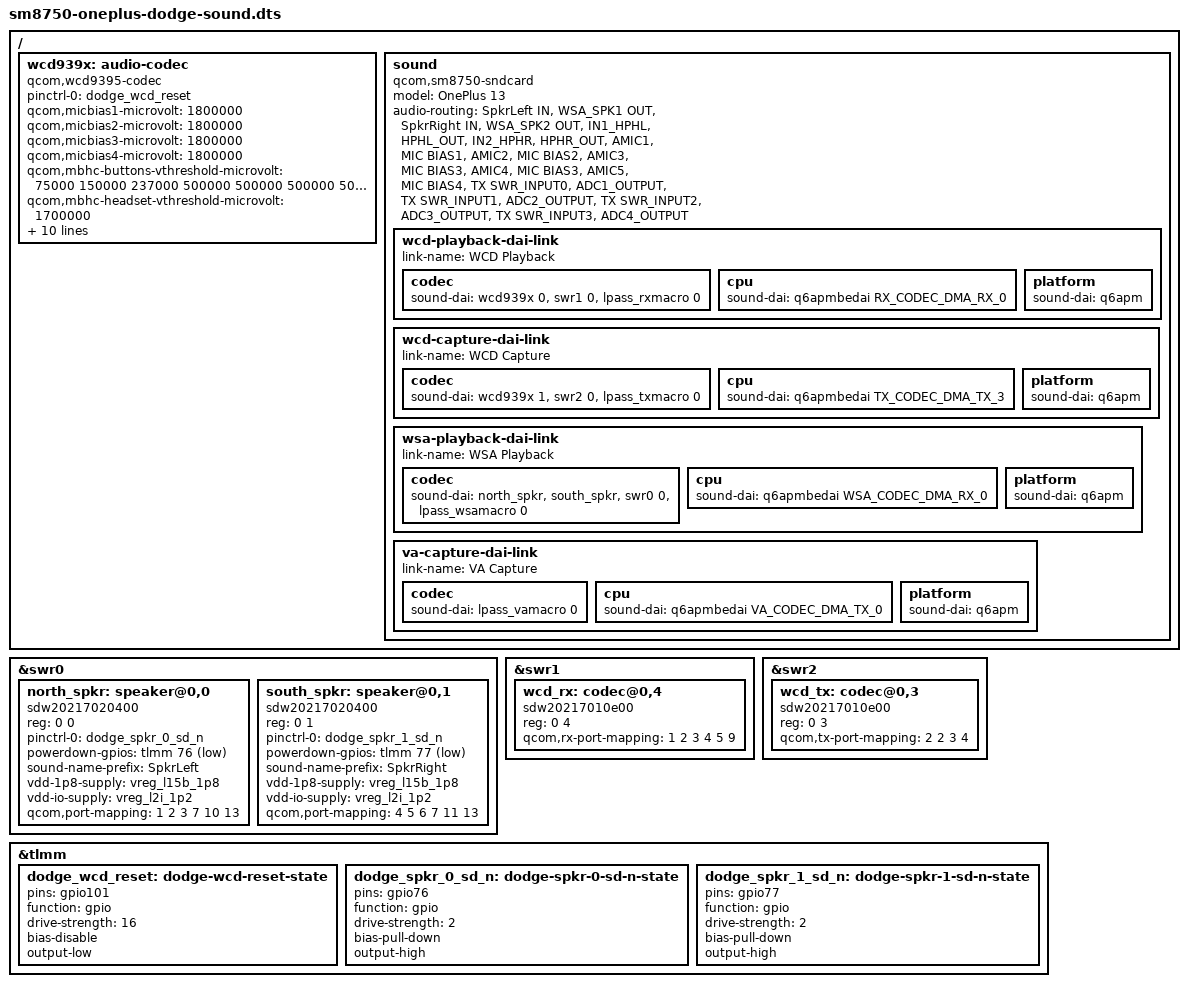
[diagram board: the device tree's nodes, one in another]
// SPDX-License-Identifier: BSD-3-Clause
/*
 * SM8750 Audioreach sound card for the OnePlus 13 (dodge).
 * Structure after sm8750-qrd.dts @ 7a81d184e309 (the upstream QRD template);
 * phone-specific facts from the owner's stock FDT (runtime.dtb, PJZ110):
 *   - WCD939x codec, reset on tlmm gpio101 (stock wcd939x_reset_active)
 *   - first WSA884x speaker pair on swr0, shutdown pins tlmm gpio76/77
 *     (stock spkr_02_sd_n / spkr_13_sd_n), SWR addresses 0x02170220/21
 *   - supplies l15b 1.8V / l2i 1.2V / bob1 match the QRD wiring table
 * The second WSA pair (swr3) and the two AW882xx I2C amplifiers are not
 * described yet; the AW88261 kernel config is off in this kernel series.
 * Experimental audio-only candidate; not hardware validated.
 */
#include "sm8750-oneplus-dodge.dts"
#include <dt-bindings/sound/qcom,q6dsp-lpass-ports.h>

/ {
	wcd939x: audio-codec {
		compatible = "qcom,wcd9395-codec", "qcom,wcd9390-codec";

		pinctrl-0 = <&dodge_wcd_reset>;
		pinctrl-names = "default";

		qcom,micbias1-microvolt = <1800000>;
		qcom,micbias2-microvolt = <1800000>;
		qcom,micbias3-microvolt = <1800000>;
		qcom,micbias4-microvolt = <1800000>;
		qcom,mbhc-buttons-vthreshold-microvolt = <75000 150000 237000 500000 500000 500000 500000 500000>;
		qcom,mbhc-headset-vthreshold-microvolt = <1700000>;
		qcom,mbhc-headphone-vthreshold-microvolt = <50000>;
		qcom,rx-device = <&wcd_rx>;
		qcom,tx-device = <&wcd_tx>;

		reset-gpios = <&tlmm 101 GPIO_ACTIVE_LOW>;

		vdd-buck-supply = <&vreg_l15b_1p8>;
		vdd-rxtx-supply = <&vreg_l15b_1p8>;
		vdd-io-supply = <&vreg_l15b_1p8>;
		vdd-mic-bias-supply = <&vreg_bob1>;
		vdd-px-supply = <&vreg_l15b_1p8>;

		#sound-dai-cells = <1>;
	};

	sound {
		compatible = "qcom,sm8750-sndcard", "qcom,sm8450-sndcard";
		model = "OnePlus 13";
		audio-routing = "SpkrLeft IN", "WSA_SPK1 OUT",
				"SpkrRight IN", "WSA_SPK2 OUT",
				"IN1_HPHL", "HPHL_OUT",
				"IN2_HPHR", "HPHR_OUT",
				"AMIC1", "MIC BIAS1",
				"AMIC2", "MIC BIAS2",
				"AMIC3", "MIC BIAS3",
				"AMIC4", "MIC BIAS3",
				"AMIC5", "MIC BIAS4",
				"TX SWR_INPUT0", "ADC1_OUTPUT",
				"TX SWR_INPUT1", "ADC2_OUTPUT",
				"TX SWR_INPUT2", "ADC3_OUTPUT",
				"TX SWR_INPUT3", "ADC4_OUTPUT";

		wcd-playback-dai-link {
			link-name = "WCD Playback";

			codec {
				sound-dai = <&wcd939x 0>, <&swr1 0>, <&lpass_rxmacro 0>;
			};

			cpu {
				sound-dai = <&q6apmbedai RX_CODEC_DMA_RX_0>;
			};

			platform {
				sound-dai = <&q6apm>;
			};
		};

		wcd-capture-dai-link {
			link-name = "WCD Capture";

			codec {
				sound-dai = <&wcd939x 1>, <&swr2 0>, <&lpass_txmacro 0>;
			};

			cpu {
				sound-dai = <&q6apmbedai TX_CODEC_DMA_TX_3>;
			};

			platform {
				sound-dai = <&q6apm>;
			};
		};

		wsa-playback-dai-link {
			link-name = "WSA Playback";

			codec {
				sound-dai = <&north_spkr>, <&south_spkr>, <&swr0 0>, <&lpass_wsamacro 0>;
			};

			cpu {
				sound-dai = <&q6apmbedai WSA_CODEC_DMA_RX_0>;
			};

			platform {
				sound-dai = <&q6apm>;
			};
		};

		va-capture-dai-link {
			link-name = "VA Capture";

			codec {
				sound-dai = <&lpass_vamacro 0>;
			};

			cpu {
				sound-dai = <&q6apmbedai VA_CODEC_DMA_TX_0>;
			};

			platform {
				sound-dai = <&q6apm>;
			};
		};
	};
};

&swr0 {
	status = "okay";

	/* WSA884x, stock sound-name-prefix SpkrLeft/SpkrRight */
	north_spkr: speaker@0,0 {
		compatible = "sdw20217020400";
		reg = <0 0>;
		pinctrl-0 = <&dodge_spkr_0_sd_n>;
		pinctrl-names = "default";
		powerdown-gpios = <&tlmm 76 GPIO_ACTIVE_LOW>;
		#sound-dai-cells = <0>;
		sound-name-prefix = "SpkrLeft";
		vdd-1p8-supply = <&vreg_l15b_1p8>;
		vdd-io-supply = <&vreg_l2i_1p2>;
		qcom,port-mapping = <1 2 3 7 10 13>;
	};

	south_spkr: speaker@0,1 {
		compatible = "sdw20217020400";
		reg = <0 1>;
		pinctrl-0 = <&dodge_spkr_1_sd_n>;
		pinctrl-names = "default";
		powerdown-gpios = <&tlmm 77 GPIO_ACTIVE_LOW>;
		#sound-dai-cells = <0>;
		sound-name-prefix = "SpkrRight";
		vdd-1p8-supply = <&vreg_l15b_1p8>;
		vdd-io-supply = <&vreg_l2i_1p2>;
		qcom,port-mapping = <4 5 6 7 11 13>;
	};
};

&swr1 {
	status = "okay";

	/* WCD9395 RX */
	wcd_rx: codec@0,4 {
		compatible = "sdw20217010e00";
		reg = <0 4>;
		qcom,rx-port-mapping = <1 2 3 4 5 9>;
	};
};

&swr2 {
	status = "okay";

	/* WCD9395 TX */
	wcd_tx: codec@0,3 {
		compatible = "sdw20217010e00";
		reg = <0 3>;
		qcom,tx-port-mapping = <2 2 3 4>;
	};
};

&tlmm {
	dodge_wcd_reset: dodge-wcd-reset-state {
		pins = "gpio101";
		function = "gpio";
		drive-strength = <16>;
		bias-disable;
		output-low;
	};

	dodge_spkr_0_sd_n: dodge-spkr-0-sd-n-state {
		pins = "gpio76";
		function = "gpio";
		drive-strength = <2>;
		bias-pull-down;
		output-high;
	};

	dodge_spkr_1_sd_n: dodge-spkr-1-sd-n-state {
		pins = "gpio77";
		function = "gpio";
		drive-strength = <2>;
		bias-pull-down;
		output-high;
	};
};
